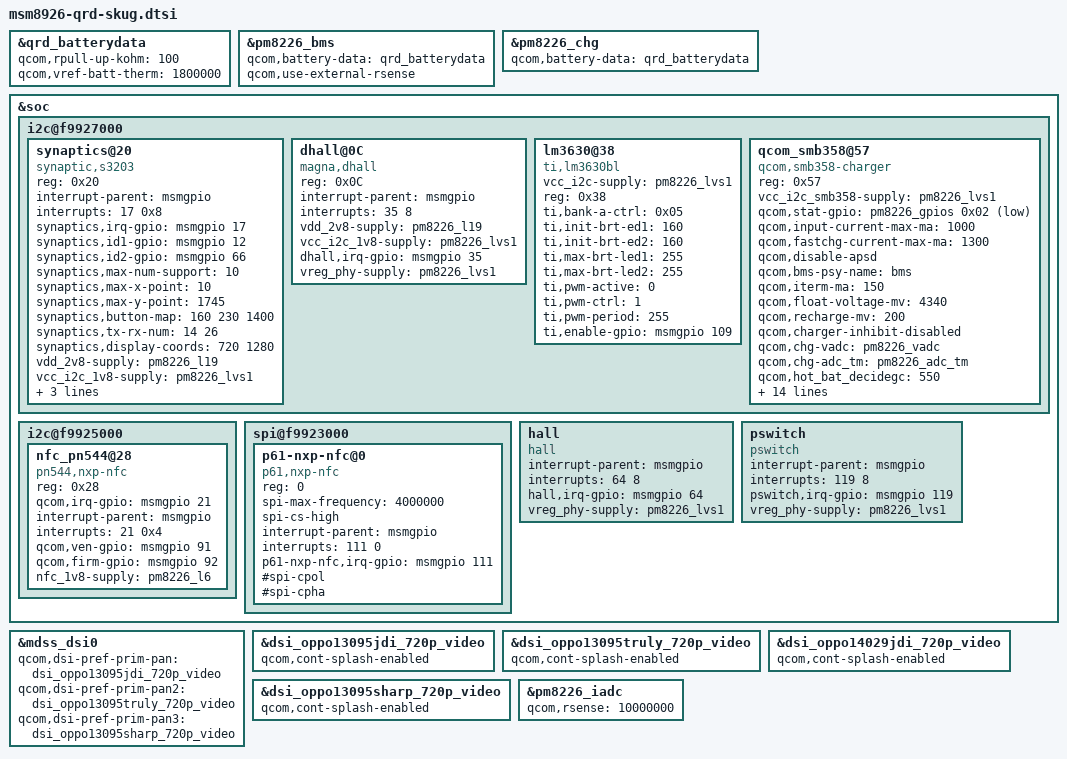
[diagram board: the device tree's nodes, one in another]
/* Copyright (c) 2013, The Linux Foundation. All rights reserved.
 *
 * This program is free software; you can redistribute it and/or modify
 * it under the terms of the GNU General Public License version 2 and
 * only version 2 as published by the Free Software Foundation.
 *
 * This program is distributed in the hope that it will be useful,
 * but WITHOUT ANY WARRANTY; without even the implied warranty of
 * MERCHANTABILITY or FITNESS FOR A PARTICULAR PURPOSE.  See the
 * GNU General Public License for more details.
 */

/include/ "msm8926.dtsi"
/include/ "msm8226-qrd.dtsi"
/*zhangzr delete for camera
/include/ "msm8926-camera-sensor-qrd.dtsi"
zhangzr delete end*/

&qrd_batterydata {
	qcom,rpull-up-kohm = <100>;
	qcom,vref-batt-therm = <1800000>;

	/include/ "batterydata-qrd-4v2-2000mah.dtsi"
};

&pm8226_bms {
	qcom,battery-data = <&qrd_batterydata>;
	qcom,use-external-rsense;
};

&pm8226_chg {
	qcom,battery-data = <&qrd_batterydata>;
};

&soc {
	i2c@f9927000 { /* BLSP1 QUP5 */
		
		synaptics@20 {/*tong.han add for TP */
			compatible = "synaptic,s3203";
			reg = <0x20>;
			interrupt-parent = <&msmgpio>;
			interrupts = <17 0x8>;
			synaptics,irq-gpio = <&msmgpio 17 0x00>;
		        synaptics,id1-gpio = <&msmgpio 12 0x00>;
	         	synaptics,id2-gpio = <&msmgpio 66 0x00>;
			/*synaptics,id3-gpio = <&msmgpio 119 0x00>;*/
			synaptics,max-num-support = <10>;
			synaptics,max-x-point = <10>;
			synaptics,max-y-point = <1745>;
			synaptics,button-map= <160 230 1400>;//width-height-y.position
			synaptics,tx-rx-num = <14 26>;
			synaptics,display-coords = <720 1280>;
			vdd_2v8-supply = <&pm8226_l19>;
			vcc_i2c_1v8-supply = <&pm8226_lvs1>;
			synaptics,i2c-pull-up;
			synaptics,power-down;
			synaptics,disable-gpios;
		};
		/*LiuPing@proDrv.Sen,2014-03-05, add for dhall sensor, m1120*/
		dhall@0C {
			compatible = "magna,dhall";
			reg = <0x0C>;
			interrupt-parent = <&msmgpio>;
			interrupts = <35 8>;
			vdd_2v8-supply = <&pm8226_l19>;
			vcc_i2c_1v8-supply = <&pm8226_lvs1>;			
			dhall,irq-gpio = <&msmgpio 35 0x2008>;
			vreg_phy-supply = <&pm8226_lvs1>;
		};
		lm3630@38 {/*Yixue.Ge add for lcd backlight */
			compatible = "ti,lm3630bl";
			vcc_i2c-supply = <&pm8226_lvs1>;
			reg = <0x38>;
			ti,bank-a-ctrl = <0x05>;
			ti,init-brt-ed1 = <160>;
			ti,init-brt-ed2 = <160>;
			ti,max-brt-led1 = <255>;
			ti,max-brt-led2 = <255>;
			ti,pwm-active = <0>;
			ti,pwm-ctrl = <1>;
			ti,pwm-period = <255>;
			ti,enable-gpio = <&msmgpio 109 0x00>;
		};
		
		qcom_smb358@57 {
			compatible = "qcom,smb358-charger";
			reg = <0x57>;
			vcc_i2c_smb358-supply = <&pm8226_lvs1>;
			/*
			#ifndef VENDOR_ENDIT
			interrupt-parent = <&msmgpio>;
			interrupts = <17 0x2>;
			qcom,irq-gpio = <&msmgpio 17 0x00>;
			qcom,chg-valid-gpio = <&msmgpio 0x02 0x00>; */
			/*#else*/
			qcom,stat-gpio = <&pm8226_gpios 0x02 0x01>;
			/*#endif*/
			qcom,input-current-max-ma = <1000>;
			qcom,fastchg-current-max-ma = <1300>;
			qcom,disable-apsd;
			qcom,bms-psy-name = "bms";
			qcom,iterm-ma = <150>;
			qcom,float-voltage-mv = <4340>;
			qcom,recharge-mv = <200>;
			qcom,charger-inhibit-disabled;
			qcom,chg-vadc = <&pm8226_vadc>;
			qcom,chg-adc_tm = <&pm8226_adc_tm>;
			qcom,hot_bat_decidegc = <550>;
			qcom,warm_bat_decidegc = <450>;
			qcom,little_cool_bat_decidegc = <50>;
			qcom,cool_bat_decidegc = <0>;
			qcom,cold_bat_decidegc = <100>;
			qcom,bat_present_decidegc = <200>;
			qcom,temp_cool_vfloat_mv = <4020>;
			qcom,temp_cool_fastchg_current_ma = <250>;
			qcom,temp_little_cool_vfloat_mv = <4220>;
			qcom,temp_little_cool_fastchg_current_ma = <750>;
			qcom,temp_warm_vfloat_mv = <4120>;
			qcom,temp_warm_fastchg_current_ma = <750>;
			qcom,non_standard_vfloat_mv = <4220>;
			qcom,non_standard_fastchg_current_ma = <750>;
			regulator-name = "boost_for_otg";
		};
	};
	/*OPPO yuyi 2014-03-25 add bein for nfc devicetree*/
	i2c@f9925000 { /* BLSP-1 QUP-3 */
		nfc_pn544@28{/*zhanhua.li add for nfc pn544 65t*/
			compatible= "pn544,nxp-nfc";
			reg = <0x28>;
			qcom,irq-gpio = <&msmgpio 21 0x00>;
			interrupt-parent = <&msmgpio>;
			interrupts = <21 0x4>;	
			qcom,ven-gpio = <&msmgpio 91 0x00>;
			qcom,firm-gpio = <&msmgpio 92 0x00>;	
			nfc_1v8-supply = <&pm8226_l6>;			
		};	
	};
	/*OPPO yuyi 2014-03-18 add end for NFC spi clk*/
	/*ifdef  CONFIG_VENDOR_EDIT*/
	spi@f9923000 {
		p61-nxp-nfc@0 { //Slave driver and CS ID
			compatible = "p61,nxp-nfc"; //Manufacture, and Model
			reg = <0>; //Same as CS ID
			spi-max-frequency = <4000000>; //Max Frequency for Device
			spi-cs-high; //CS Active High
			interrupt-parent = <&msmgpio>; //GPIO Handler
			interrupts = <111 0>; //GPIO # and flags
			p61-nxp-nfc,irq-gpio = <&msmgpio 111 0x00>; //Pass a GPIO
			#spi-cpol; //CPOL bit set for SPI polarity
			#spi-cpha; //CPHA bit set for SPI Phase
		};
	};
	/*endif*/
	/*OPPO yuyi 2014-03-25 add end for nfc devicetree*/

	/*ye.zhang@proDrv.Sen,2014-01-08, add for hall sensor*/
	hall {
		compatible = "hall";
		interrupt-parent = <&msmgpio>;
		interrupts = <64 8>;
		hall,irq-gpio = <&msmgpio 64 0x2008>;
		vreg_phy-supply = <&pm8226_lvs1>;
	};
	/* LiuPing@proDrv.Sen, 2014-03-21,add for pswtitch */
	pswitch {
		compatible = "pswitch";
		interrupt-parent = <&msmgpio>;
		interrupts = <119 8>;
		pswitch,irq-gpio = <&msmgpio 119 0x2008>;
		vreg_phy-supply = <&pm8226_lvs1>;
	};	
};

/*Lycan.Wang@Prd.BasicDrv, 2014-02-22 Remove for button-backlight*/
/*&spmi_bus {
	qcom,pm8226@0 {
		qcom,leds@a100 {
			status = "disable";
			};
		};
};*/

/*yixue.ge modify*/
&mdss_dsi0 {
	/*qcom,dsi-pref-prim-pan = <&dsi_ssd2080m_720_vid>;*/
	qcom,dsi-pref-prim-pan = <&dsi_oppo13095jdi_720p_video>;
	qcom,dsi-pref-prim-pan2 = <&dsi_oppo13095truly_720p_video>;
	qcom,dsi-pref-prim-pan3 = <&dsi_oppo13095sharp_720p_video>;
};
/*yixue.ge add*/
&dsi_oppo13095jdi_720p_video {
	qcom,cont-splash-enabled;
};
/*tong.han add*/
&dsi_oppo13095truly_720p_video {
	qcom,cont-splash-enabled;
};
/*yixue.ge add*/
&dsi_oppo14029jdi_720p_video {
	qcom,cont-splash-enabled;
};
/*tong.han add*/
&dsi_oppo13095sharp_720p_video {
	qcom,cont-splash-enabled;
};
/*yixue.ge del*/
/*&dsi_ssd2080m_720_vid {
	qcom,cont-splash-enabled;
};*/

/* use external rsense here */
&pm8226_iadc {
        qcom,rsense = <10000000>;
};

